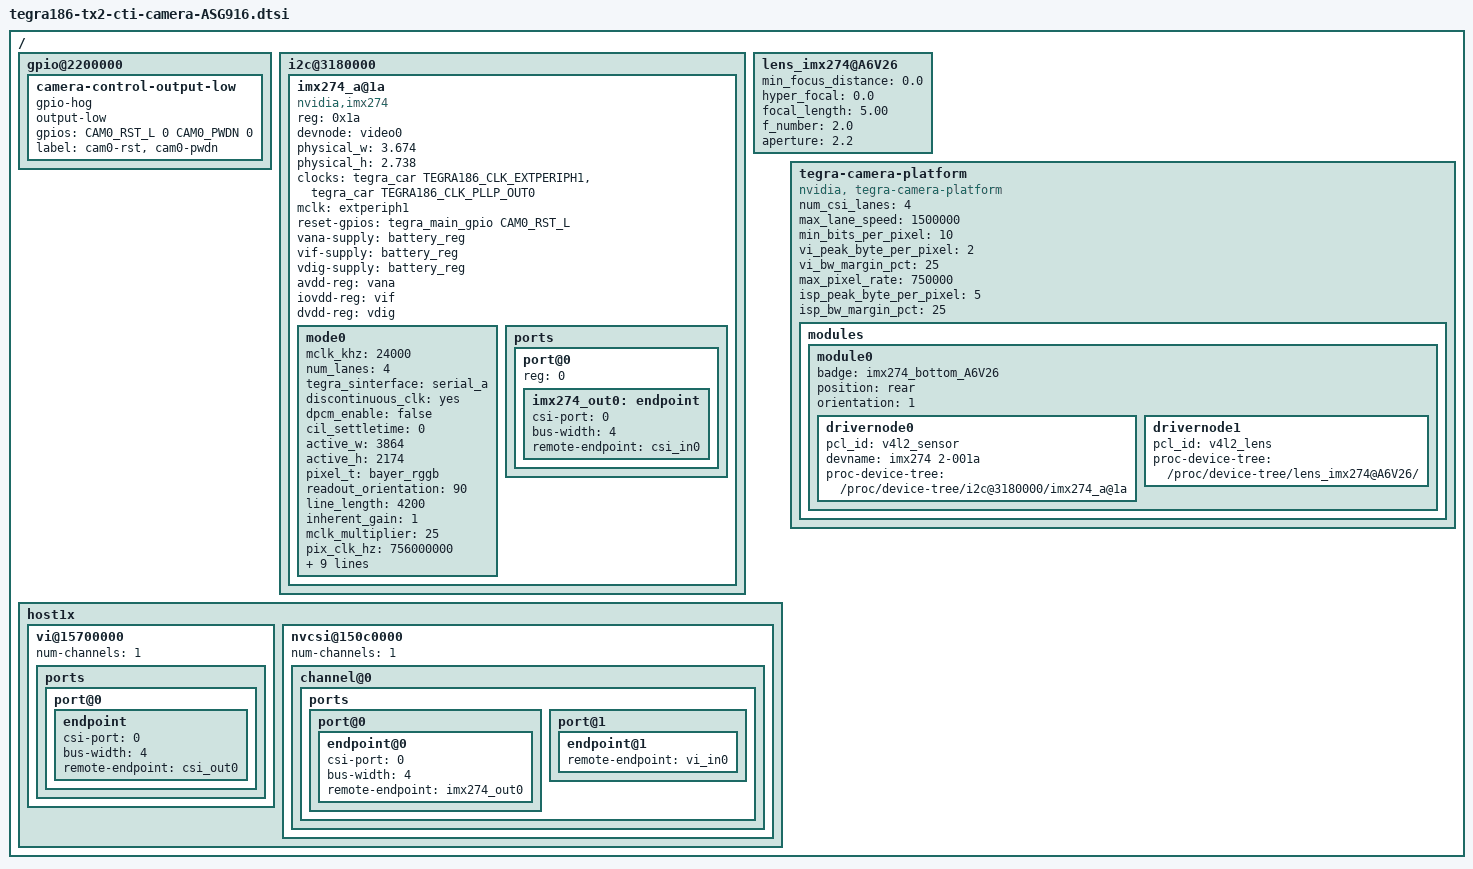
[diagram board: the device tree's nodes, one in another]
    

#include <t18x-common-platforms/tegra186-tx2-cti-camera-base.dtsi>
#include "dt-bindings/clock/tegra186-clock.h"


/* camera control gpio definitions */
#define CAM0_RST_L  TEGRA_MAIN_GPIO(R, 5)
#define CAM0_PWDN   TEGRA_MAIN_GPIO(R, 0)

/ {
    gpio@2200000 {
        camera-control-output-low {
            gpio-hog;
            output-low;
            gpios = <CAM0_RST_L 0 CAM0_PWDN 0>;
            label = "cam0-rst", "cam0-pwdn";
            status = "okay";
        };
    };


	i2c@3180000 {       //set this to correct i2c bus

        imx274_a@1a {
            compatible = "nvidia,imx274";
            reg = <0x1a>;
            devnode = "video0";

            /* Physical dimensions of sensor */
            physical_w = "3.674";
            physical_h = "2.738";
            clocks = <&tegra_car TEGRA186_CLK_EXTPERIPH1>,
                     <&tegra_car TEGRA186_CLK_PLLP_OUT0>;
            clock-names = "extperiph1", "pllp_grtba";
            mclk = "extperiph1";
            reset-gpios = <&tegra_main_gpio CAM0_RST_L GPIO_ACTIVE_HIGH>;
            vana-supply = <&battery_reg>;
            vif-supply = <&battery_reg>;
            vdig-supply = <&battery_reg>;


            /* Define any required hw resources needed by driver */
            /* ie. clocks, io pins, power sources */
            avdd-reg = "vana";
            iovdd-reg = "vif";
            dvdd-reg = "vdig";

            mode0 {
                mclk_khz = "24000";
                num_lanes = "4";
                tegra_sinterface = "serial_a";
                discontinuous_clk = "yes";
                dpcm_enable = "false";
                cil_settletime = "0";

                active_w = "3864";
                active_h = "2174";
                pixel_t = "bayer_rggb";
                readout_orientation = "90";
                line_length = "4200";
                inherent_gain = "1";
                mclk_multiplier = "25";
                pix_clk_hz = "756000000";

                min_gain_val = "1.0";
                max_gain_val = "22.2";
                min_hdr_ratio = "1";
                max_hdr_ratio = "64";
                min_framerate = "1.462526";
                max_framerate = "60";
                min_exp_time = "16.165";
                max_exp_time = "165770";
                embedded_metadata_height = "1";
            };

            ports {
                #address-cells = <1>;
                #size-cells = <0>;

                port@0 {
                    reg = <0>;
                    imx274_out0: endpoint {
                        csi-port = <0>;
                        bus-width = <4>;
                        remote-endpoint = <&csi_in0>;
                    };
                };
            };
        };
    };


    lens_imx274@A6V26 {
        min_focus_distance = "0.0";
        hyper_focal = "0.0";
        focal_length = "5.00";
        f_number = "2.0";
        aperture = "2.2";
    };


	gpio@2200000 {
		camera-control-output-low {
			gpio-hog;
			output-low;
			gpios = <CAM0_RST_L 0 CAM0_PWDN 0>;
			label = "cam0-rst", "cam0-pwdn";
		};
	};

     host1x {
        vi@15700000 {
            num-channels = <1>; //set number of channels
            status = "okay";
            ports {
                port@0 {
                    status = "okay";
                    endpoint {
                        status = "okay";
                        csi-port = <0>;
                        bus-width = <4>;
                        remote-endpoint = <&csi_out0>; 
                    };
                };
            };
        };
        nvcsi@150c0000 {
            num-channels = <1>;
            channel@0 {
                status = "okay";
                ports {
                    port@0 {
                        status = "okay";
                        endpoint@0 {
                            csi-port = <0>;
                            bus-width = <4>;
                            remote-endpoint = <&imx274_out0>; //should be sensor port under i2c endpoint
                            status = "okay";
                        };
                    };
                    port@1 {
                        status = "okay";
                        endpoint@1 {
                            status = "okay";
                            remote-endpoint = <&vi_in0>; 
                        };
                    };
                };
            };
        };
    };

    lens_imx274@A6V26 {
        min_focus_distance = "0.0";
        hyper_focal = "0.0";
        focal_length = "5.00";
        f_number = "2.0";
        aperture = "2.2";
    };

    tegra-camera-platform {
        compatible = "nvidia, tegra-camera-platform";

        status = "okay";
        num_csi_lanes = <4>;
        max_lane_speed = <1500000>;
        min_bits_per_pixel = <10>;
        vi_peak_byte_per_pixel = <2>;
        vi_bw_margin_pct = <25>;
        max_pixel_rate = <750000>;
        isp_peak_byte_per_pixel = <5>;
        isp_bw_margin_pct = <25>;
        modules {
            module0 {
                status = "okay";
                badge = "imx274_bottom_A6V26";
                position = "rear";
                orientation = "1";
                drivernode0 {
                    /* Declare PCL support driver (classically known as guid)  */
                    status = "okay";
                    pcl_id = "v4l2_sensor";
                    /* Driver v4l2 device name */
                    devname = "imx274 2-001a";  //set the bus and address of the sensor here 
                    /* Declare the device-tree hierarchy to driver instance */
                    proc-device-tree = "/proc/device-tree/i2c@3180000/imx274_a@1a"; //this has to match the camera driver node under i2c 
                };
                drivernode1 {
                    /* Declare PCL support driver (classically known as guid)  */
                    status = "okay";
                    pcl_id = "v4l2_lens";
                    proc-device-tree = "/proc/device-tree/lens_imx274@A6V26/";
                };
            };
        };
    };
};
